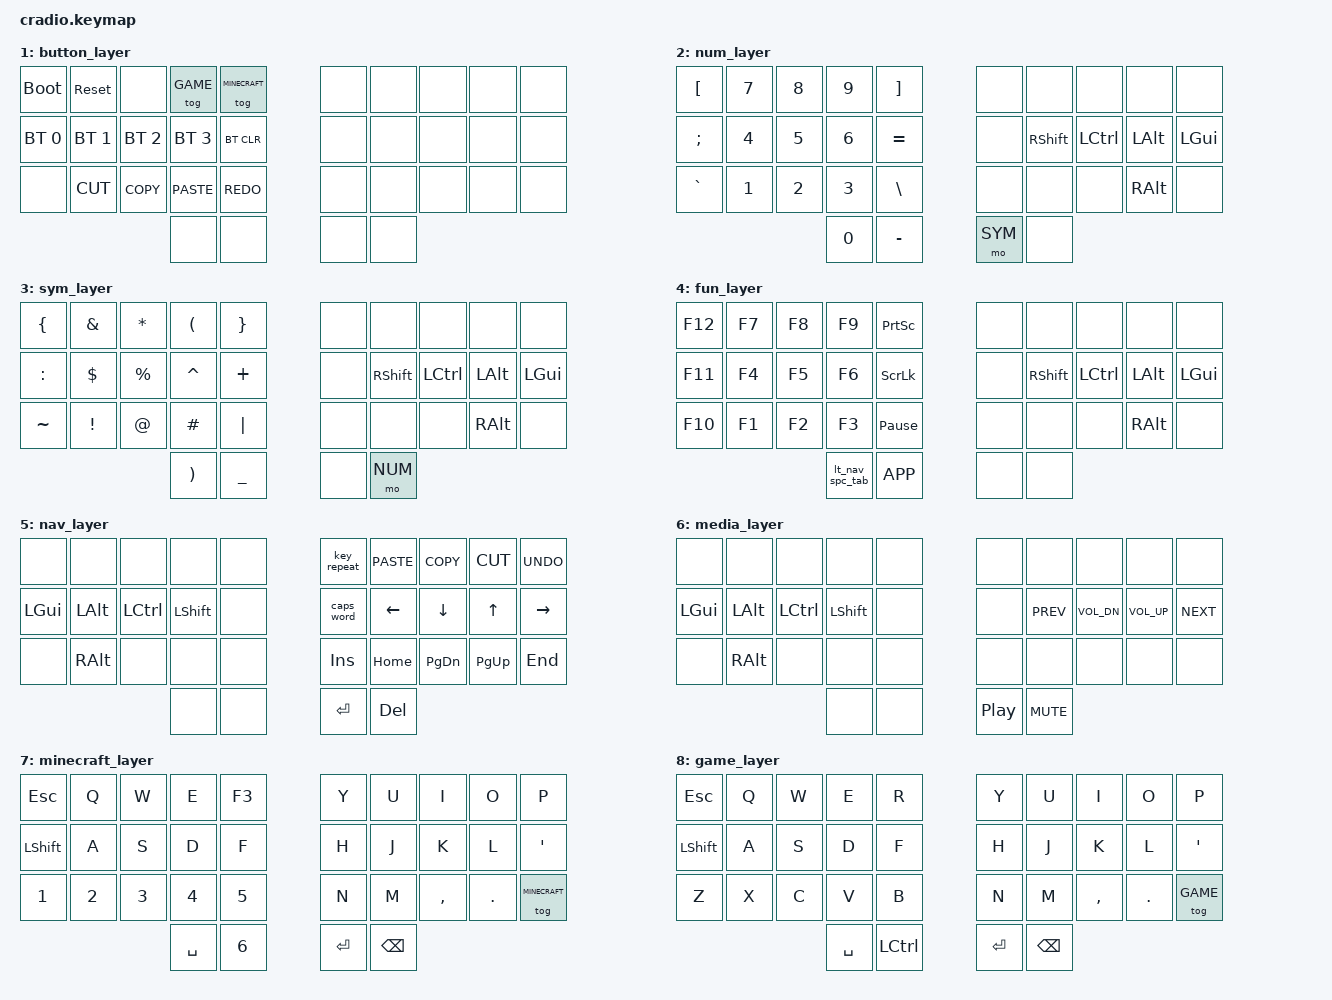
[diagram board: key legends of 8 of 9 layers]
// Copyright (c) 2022 The ZMK Contributors
// SPDX-License-Identifier: MIT

#include <behaviors.dtsi>
#include <dt-bindings/zmk/keys.h>
#include <dt-bindings/zmk/bt.h>

#define HOST_OS 1 // sets os to linux, necessary for unicode characters
#include "zmk-helpers/helper.h"
#include "zmk-helpers/unicode-chars/danish.dtsi"

// Home row mods macro
#define HRML(k1,k2,k3,k4) &ht LGUI  k1  &ht LALT  k2  &ht LCTRL k3  &ht LSHFT k4
#define HRMR(k1,k2,k3,k4) &ht RSHFT k1  &ht LCTRL k2  &ht LALT  k3  &ht LGUI  k4
#define HRML_R3(k2,k3,k4) &ht LALT  k2  &ht LCTRL k3  &ht LSHFT k4

#define BASE      0
#define BUTTON    1
#define NUM       2
#define SYM       3
#define FUN       4
#define NAV       5
#define MEDIA     6
#define MINECRAFT 7
#define GAME      8
// #define MOUSE  9

/ {
    behaviors {
        ht: hold_tap {
            compatible = "zmk,behavior-hold-tap";
            #binding-cells = <2>;
            flavor = "tap-preferred";
            tapping-term-ms = <220>;
            quick-tap-ms = <150>;
            require-prior-idle-ms = <100>;
            bindings = <&kp>, <&kp>;
        };
        lt_nav_spc_tab_ctrl: lt_nav_space_tab_ctrl {
            compatible = "zmk,behavior-mod-morph";
            #binding-cells = <0>;
            bindings = <&lt NAV TAB>, <&lt NAV LS(LC(SPACE))>;
            mods = <(MOD_LCTL|MOD_RCTL)>;
        };     
        lt_nav_spc_tab: lt_nav_space_tab {
            compatible = "zmk,behavior-mod-morph";
            #binding-cells = <0>;
            bindings = <&lt NAV SPACE>, <&lt_nav_spc_tab_ctrl>;
            mods = <(MOD_RSFT)>;
        };     
        lt_num_bspc_del: lt_num_backspace_delete {
            compatible = "zmk,behavior-mod-morph";
            #binding-cells = <0>;
            bindings = <&lt NUM BACKSPACE>, <&lt NUM DELETE>;
            mods = <(MOD_LSFT|MOD_RSFT)>;
        };
        // e_ae: ht_gui_e_ae {
        //     compatible = "zmk,behavior-mod-morph";
        //     #binding-cells = <0>;
        //     bindings = <&kp E>, <&kp &da_ae>;
        //     mods = <(MOD_LALT|MOD_RALT)>;
        // };
        // o_oe: ht_gui_o_oe {
        //     compatible = "zmk,behavior-mod-morph";
        //     #binding-cells = <0>;
        //     bindings = <&kp O>, <&kp &da_oe>;
        //     mods = <(MOD_LALT|MOD_RALT)>;
        // };
        // gui_a_aa: ht_gui_a_aa {
        //     compatible = "zmk,behavior-mod-morph";
        //     #binding-cells = <0>;
        //     bindings = <&ht LGUI A>, <&ht LGUI &da_aa>;
        //     mods = <(MOD_LALT|MOD_RALT)>;
        // };
    };

    conditional_layers {
        compatible = "zmk,conditional-layers";
        tri_layer {
            if-layers = <NUM SYM>;
            then-layer = <FUN>;
        };
    };

    keymap {
        compatible = "zmk,keymap";
        default_layer {
            bindings = <
        //╭──────────┬──────────┬──────────┬──────────┬──────────╮   ╭──────────┬──────────┬──────────┬──────────┬──────────╮
        //│  Q       │  W       │  E       │  R       │  T       │   │  Y       │  U       │  I       │  O       │  P       │
             &kp Q      &kp W      &kp E      &kp R      &kp T          &kp Y      &kp U      &kp I      &kp O      &kp P
        //├──────────┼──────────┼──────────┼──────────┼──────────┤   ├──────────┼──────────┼──────────┼──────────┼──────────┤
        //│  A       │  S       │  D       │  F       │  G       │   │  H       │  J       │  K       │  L       │ ' "      │
            HRML(A,     S,         D,         F)         &kp G          &kp H      HRMR(J,        K,         L,        SQT)
        //├──────────┼──────────┼──────────┼──────────┼──────────┤   ├──────────┼──────────┼──────────┼──────────┼──────────┤
        //│  Z       │  X       │  C       │  V       │  B       │   │  N       │  M       │ , <      │ . >      │ / ?      │
          &lt BUTTON Z &ht RALT X  &kp C      &kp V      &kp B          &kp N      &kp M    &kp COMMA &ht RALT DOT &kp FSLH
        //╰──────────┴──────────┴──────────┼──────────┼──────────┤   ├──────────┼──────────┼──────────┴──────────┴──────────╯
                                      &lt_nav_spc_tab &lt MEDIA ESC &lt SYM ENTER &lt_num_bspc_del
        //                                 ╰──────────┴──────────╯   ╰──────────┴──────────╯
            >;
        };

        button_layer {
          bindings = <
        //╭──────────┬──────────┬──────────┬──────────┬──────────╮   ╭──────────┬──────────┬──────────┬──────────┬──────────╮
        //│          │          │          │          │          │   │          │          │          │          │          │
           &bootloader &sys_reset  &none    &tog GAME &tog MINECRAFT    &none      &none      &none      &none      &none
        //├──────────┼──────────┼──────────┼──────────┼──────────┤   ├──────────┼──────────┼──────────┼──────────┼──────────┤
        //│          │          │          │          │          │   │          │          │          │          │          │
       &bt BT_SEL 0 &bt BT_SEL 1 &bt BT_SEL 2 &bt BT_SEL 3 &bt BT_CLR   &none      &none      &none      &none      &none
        //├──────────┼──────────┼──────────┼──────────┼──────────┤   ├──────────┼──────────┼──────────┼──────────┼──────────┤
        //│          │          │          │          │          │   │          │          │          │          │          │
             &none    &kp K_CUT  &kp K_COPY &kp K_PASTE &kp K_REDO      &none      &none      &none      &none      &none
        //╰──────────┴──────────┴──────────┼──────────┼──────────┤   ├──────────┼──────────┼──────────┴──────────┴──────────╯
                                              &none      &none          &none      &none
        //                                 ╰──────────┴──────────╯   ╰──────────┴──────────╯
          >;
        };

        num_layer {
            bindings = <
        //╭──────────┬──────────┬──────────┬──────────┬──────────╮   ╭──────────┬──────────┬──────────┬──────────┬──────────╮
        //│          │          │          │          │          │   │          │          │          │          │          │
            &kp LBKT    &kp N7     &kp N8     &kp N9    &kp RBKT        &none      &none      &none      &none      &none     
        //├──────────┼──────────┼──────────┼──────────┼──────────┤   ├──────────┼──────────┼──────────┼──────────┼──────────┤
        //│          │          │          │          │          │   │          │          │          │          │          │
            &kp SEMI    &kp N4     &kp N5     &kp N6    &kp EQUAL       &none    &kp RSHIFT  &kp LCTRL  &kp LALT   &kp LGUI
        //├──────────┼──────────┼──────────┼──────────┼──────────┤   ├──────────┼──────────┼──────────┼──────────┼──────────┤
        //│          │          │          │          │          │   │          │          │          │          │          │
            &kp GRAVE   &kp N1     &kp N2     &kp N3    &kp BSLH        &none      &none      &none     &kp RALT    &none     
        //╰──────────┴──────────┴──────────┼──────────┼──────────┤   ├──────────┼──────────┼──────────┴──────────┴──────────╯
                                              &kp N0    &kp MINUS      &mo SYM     &none        
        //                                 ╰──────────┴──────────╯   ╰──────────┴──────────╯
             >;
        };

        sym_layer {
          bindings = <
        //╭──────────┬──────────┬──────────┬──────────┬──────────╮   ╭──────────┬──────────┬──────────┬──────────┬──────────╮
        //│          │          │          │          │          │   │          │          │          │          │          │
            &kp LBRC   &kp AMPS   &kp STAR   &kp LPAR   &kp RBRC        &none      &none      &none      &none      &none    
        //├──────────┼──────────┼──────────┼──────────┼──────────┤   ├──────────┼──────────┼──────────┼──────────┼──────────┤
        //│          │          │          │          │          │   │          │          │          │          │          │
            &kp COLON  &kp DLLR   &kp PRCNT  &kp CARET  &kp PLUS        &none    &kp RSHIFT  &kp LCTRL  &kp LALT   &kp LGUI
        //├──────────┼──────────┼──────────┼──────────┼──────────┤   ├──────────┼──────────┼──────────┼──────────┼──────────┤
        //│          │          │          │          │          │   │          │          │          │          │          │
            &kp TILDE  &kp EXCL    &kp AT    &kp HASH   &kp PIPE        &none      &none      &none     &kp RALT    &none    
        //╰──────────┴──────────┴──────────┼──────────┼──────────┤   ├──────────┼──────────┼──────────┴──────────┴──────────╯
                                             &kp RPAR   &kp UNDER       &none     &mo NUM        
        //                                 ╰──────────┴──────────╯   ╰──────────┴──────────╯                                 
          >;
        };

        fun_layer {
          bindings = <
        //╭──────────┬──────────┬──────────┬──────────┬──────────╮   ╭──────────┬──────────┬──────────┬──────────┬──────────╮
        //│          │          │          │          │          │   │          │          │          │          │          │
            &kp F12     &kp F7     &kp F8     &kp F9   &kp PSCRN        &none      &none      &none      &none      &none    
        //├──────────┼──────────┼──────────┼──────────┼──────────┤   ├──────────┼──────────┼──────────┼──────────┼──────────┤
        //│          │          │          │          │          │   │          │          │          │          │          │
            &kp F11     &kp F4     &kp F5     &kp F6   &kp SLCK         &none    &kp RSHIFT  &kp LCTRL  &kp LALT   &kp LGUI
        //├──────────┼──────────┼──────────┼──────────┼──────────┤   ├──────────┼──────────┼──────────┼──────────┼──────────┤
        //│          │          │          │          │          │   │          │          │          │          │          │
            &kp F10     &kp F1     &kp F2     &kp F3 &kp PAUSE_BREAK    &none      &none      &none     &kp RALT    &none    
        //╰──────────┴──────────┴──────────┼──────────┼──────────┤   ├──────────┼──────────┼──────────┴──────────┴──────────╯
                                       &lt_nav_spc_tab &kp K_APP        &none      &none        
        //                                 ╰──────────┴──────────╯   ╰──────────┴──────────╯                                 
          >;
        };

        nav_layer {
          bindings = <
        //╭──────────┬──────────┬──────────┬──────────┬──────────╮   ╭──────────┬──────────┬──────────┬──────────┬──────────╮
        //│          │          │          │          │          │   │          │          │          │          │          │
             &none      &none      &none      &none      &none       &key_repeat &kp K_PASTE &kp K_COPY &kp K_CUT  &kp K_UNDO
        //├──────────┼──────────┼──────────┼──────────┼──────────┤   ├──────────┼──────────┼──────────┼──────────┼──────────┤
        //│          │          │          │          │          │   │          │          │          │          │          │
            &kp LGUI   &kp LALT   &kp LCTRL &kp LSHIFT   &none        &caps_word  &kp LEFT   &kp DOWN    &kp UP   &kp RIGHT 
        //├──────────┼──────────┼──────────┼──────────┼──────────┤   ├──────────┼──────────┼──────────┼──────────┼──────────┤
        //│          │          │          │          │          │   │          │          │          │          │          │
             &none     &kp RALT    &none      &none      &none          &kp INS   &kp HOME   &kp PG_DN  &kp PG_UP  &kp END
        //╰──────────┴──────────┴──────────┼──────────┼──────────┤   ├──────────┼──────────┼──────────┴──────────┴──────────╯
                                              &none      &none         &kp ENTER  &kp DEL
        //                                 ╰──────────┴──────────╯   ╰──────────┴──────────╯
          >;
        };

        media_layer {
          bindings = <
        //╭──────────┬──────────┬──────────┬──────────┬──────────╮   ╭──────────┬──────────┬──────────┬──────────┬──────────╮
        //│          │          │          │          │          │   │          │          │          │          │          │
             &none      &none      &none      &none      &none          &none      &none      &none      &none      &none    
        //├──────────┼──────────┼──────────┼──────────┼──────────┤   ├──────────┼──────────┼──────────┼──────────┼──────────┤
        //│          │          │          │          │          │   │          │          │          │          │          │
            &kp LGUI   &kp LALT   &kp LCTRL &kp LSHIFT   &none          &none  &kp C_PREV &kp C_VOL_DN &kp C_VOL_UP &kp C_NEXT
        //├──────────┼──────────┼──────────┼──────────┼──────────┤   ├──────────┼──────────┼──────────┼──────────┼──────────┤
        //│          │          │          │          │          │   │          │          │          │          │          │
             &none     &kp RALT    &none      &none      &none          &none      &none      &none      &none      &none              
        //╰──────────┴──────────┴──────────┼──────────┼──────────┤   ├──────────┼──────────┼──────────┴──────────┴──────────╯
                                              &none      &none     &kp C_PLAY_PAUSE &kp C_MUTE
        //                                 ╰──────────┴──────────╯   ╰──────────┴──────────╯
          >;
        };

        minecraft_layer {
            bindings = <
        //╭──────────┬──────────┬──────────┬──────────┬──────────╮   ╭──────────┬──────────┬──────────┬──────────┬──────────╮
        //│  Q       │  W       │  E       │  R       │  T       │   │  Y       │  U       │  I       │  O       │  P       │
            &kp ESC    &kp Q      &kp W      &kp E      &kp F3          &kp Y      &kp U      &kp I      &kp O      &kp P
        //├──────────┼──────────┼──────────┼──────────┼──────────┤   ├──────────┼──────────┼──────────┼──────────┼──────────┤
        //│  A       │  S       │  D       │  F       │  G       │   │  H       │  J       │  K       │  L       │ ' "      │
            &kp LSHFT  &kp A      &kp S      &kp D      &kp F          &kp H      &kp J      &kp K      &kp L      &kp SQT
        //├──────────┼──────────┼──────────┼──────────┼──────────┤   ├──────────┼──────────┼──────────┼──────────┼──────────┤
        //│  Z       │  X       │  C       │  V       │  B       │   │  N       │  M       │ , <      │ . >      │ / ?      │
            &kp N1     &kp N2     &kp N3     &kp N4     &kp N5         &kp N      &kp M     &kp COMMA   &kp DOT  &tog MINECRAFT
        //╰──────────┴──────────┴──────────┼──────────┼──────────┤   ├──────────┼──────────┼──────────┴──────────┴──────────╯
                                             &kp SPACE  &kp N6         &kp ENTER  &kp BACKSPACE
        //                                 ╰──────────┴──────────╯   ╰──────────┴──────────╯
            >;
        };

        game_layer {
            bindings = <
        //╭──────────┬──────────┬──────────┬──────────┬──────────╮   ╭──────────┬──────────┬──────────┬──────────┬──────────╮
        //│  Q       │  W       │  E       │  R       │  T       │   │  Y       │  U       │  I       │  O       │  P       │
            &kp ESC    &kp Q      &kp W      &kp E      &kp R          &kp Y      &kp U      &kp I      &kp O      &kp P
        //├──────────┼──────────┼──────────┼──────────┼──────────┤   ├──────────┼──────────┼──────────┼──────────┼──────────┤
        //│  A       │  S       │  D       │  F       │  G       │   │  H       │  J       │  K       │  L       │ ' "      │
            &kp LSHFT  &kp A      &kp S      &kp D      &kp F          &kp H      &kp J      &kp K      &kp L      &kp SQT
        //├──────────┼──────────┼──────────┼──────────┼──────────┤   ├──────────┼──────────┼──────────┼──────────┼──────────┤
        //│  Z       │  X       │  C       │  V       │  B       │   │  N       │  M       │ , <      │ . >      │ / ?      │
            &kp Z      &kp X      &kp C      &kp V      &kp B          &kp N      &kp M     &kp COMMA   &kp DOT    &tog GAME
        //╰──────────┴──────────┴──────────┼──────────┼──────────┤   ├──────────┼──────────┼──────────┴──────────┴──────────╯
                                             &kp SPACE  &kp LCTRL      &kp ENTER  &kp BACKSPACE
        //                                 ╰──────────┴──────────╯   ╰──────────┴──────────╯
            >;
        };
        // mouse_layer {
        //   bindings = <
        // //╭──────────┬──────────┬──────────┬──────────┬──────────╮   ╭──────────┬──────────┬──────────┬──────────┬──────────╮
        // //│          │          │          │          │          │   │          │          │          │          │          │
        //      &none      &none      &none      &none      &none       &key_repeat &kp K_PASTE &kp K_COPY &kp K_CUT  &kp K_UNDO
        // //├──────────┼──────────┼──────────┼──────────┼──────────┤   ├──────────┼──────────┼──────────┼──────────┼──────────┤
        // //│          │          │          │          │          │   │          │          │          │          │          │
        //      &none      &none      &none      &none      &none          &none
        // //├──────────┼──────────┼──────────┼──────────┼──────────┤   ├──────────┼──────────┼──────────┼──────────┼──────────┤
        // //│          │          │          │          │          │   │          │          │          │          │          │
        //      &none      &none      &none      &none      &none          &none 
        // //╰──────────┴──────────┴──────────┼──────────┼──────────┤   ├──────────┼──────────┼──────────┴──────────┴──────────╯
        //                                       &none      &none        &mkp LCLK  &mkp RCLK
        // //                                 ╰──────────┴──────────╯   ╰──────────┴──────────╯
        //   >;
        // };

        // fun_layer {
        //   bindings = <
        // //╭──────────┬──────────┬──────────┬──────────┬──────────╮   ╭──────────┬──────────┬──────────┬──────────┬──────────╮
        // //│          │          │          │          │          │   │          │          │          │          │          │
        // 
        // //├──────────┼──────────┼──────────┼──────────┼──────────┤   ├──────────┼──────────┼──────────┼──────────┼──────────┤
        // //│          │          │          │          │          │   │          │          │          │          │          │

        // //├──────────┼──────────┼──────────┼──────────┼──────────┤   ├──────────┼──────────┼──────────┼──────────┼──────────┤
        // //│          │          │          │          │          │   │          │          │          │          │          │

        // //╰──────────┴──────────┴──────────┼──────────┼──────────┤   ├──────────┼──────────┼──────────┴──────────┴──────────╯

        // //                                 ╰──────────┴──────────╯   ╰──────────┴──────────╯
        //   >;
        // };

        //╭──────────┬──────────┬──────────┬──────────┬──────────╮   ╭──────────┬──────────┬──────────┬──────────┬──────────╮
        //│          │          │          │          │          │   │          │          │          │          │          │
        
        //├──────────┼──────────┼──────────┼──────────┼──────────┤   ├──────────┼──────────┼──────────┼──────────┼──────────┤
        //│          │          │          │          │          │   │          │          │          │          │          │

        //├──────────┼──────────┼──────────┼──────────┼──────────┤   ├──────────┼──────────┼──────────┼──────────┼──────────┤
        //│          │          │          │          │          │   │          │          │          │          │          │

        //╰──────────┴──────────┴──────────┼──────────┼──────────┤   ├──────────┼──────────┼──────────┴──────────┴──────────╯

        //                                 ╰──────────┴──────────╯   ╰──────────┴──────────╯

        // left_layer {
        //     bindings = <
        // //╭──────────┬──────────┬──────────┬──────────┬──────────╮   ╭──────────┬──────────┬──────────┬──────────┬──────────╮
        // //│          │  [       │  {       │  }       │          │   │  ^       │  (       │  )       │  ]       │  ~       │
        //     &trans     &kp LBKT   &kp LBRC   &kp RBRC   &trans         &kp CARET  &kp LPAR   &kp RPAR   &kp RBKT   &kp TILDE
        // //├──────────┼──────────┼──────────┼──────────┼──────────┤   ├──────────┼──────────┼──────────┼──────────┼──────────┤
        // //│  !       │  @       │  #       │  $       │  %       │   │  *       │  -       │  =       │  \       │  `       │
        //     &kp EXCL   &kp AT     &kp HASH   &kp DLLR   &kp PRCNT      &kp ASTRK  &kp MINUS  &kp EQUAL  &kp BSLH   &kp GRAVE
        // //├──────────┼──────────┼──────────┼──────────┼──────────┤   ├──────────┼──────────┼──────────┼──────────┼──────────┤
        // //│          │          │          │          │          │   │  &       │  _       │  +       │  │       │          │
        //     &trans     &trans     &trans     &trans     &trans         &kp AMPS   &kp UNDER  &kp PLUS   &kp PIPE   &trans
        // //╰──────────┴──────────┴──────────┼──────────┼──────────┤   ├──────────┼──────────┼──────────┴──────────┴──────────╯
        //                                      &trans     &trans         &trans     &trans
        // //                                 ╰──────────┴──────────╯   ╰──────────┴──────────╯
        //     >;
        // };

        // tri_layer {
        //     bindings = <
        // //╭──────────┬──────────┬──────────┬──────────┬──────────╮   ╭──────────┬──────────┬──────────┬──────────┬──────────╮
        // //│ RESET    │          │          │          │PROFILE 0 │   │          │          │          │          │  RESET   │
        //    &sys_reset  &trans     &trans     &trans    &bt BT_SEL 0    &trans     &trans     &trans     &trans    &sys_reset
        // //├──────────┼──────────┼──────────┼──────────┼──────────┤   ├──────────┼──────────┼──────────┼──────────┼──────────┤
        // //│BOOTLOADER│          │          │          │PROFILE 1 │   │          │          │          │          │BOOTLOADER│
        //   &bootloader  &trans     &trans     &trans    &bt BT_SEL 1    &trans     &trans     &trans     &trans    &bootloader
        // //├──────────┼──────────┼──────────┼──────────┼──────────┤   ├──────────┼──────────┼──────────┼──────────┼──────────┤
        // //│          │          │          │ CLEAR BT │PROFILE 2 │   │          │          │          │          │          │
        //     &trans     &trans     &trans    &bt BT_CLR &bt BT_SEL 2    &trans     &trans     &trans     &trans     &trans
        // //╰──────────┴──────────┴──────────┼──────────┼──────────┤   ├──────────┼──────────┼──────────┴──────────┴──────────╯
        //                                      &trans     &trans         &trans     &trans
        // //                                 ╰──────────┴──────────╯   ╰──────────┴──────────╯
        //     >;
        // };
    };
};





//   /*
//   * Copyright (c) 2020 The ZMK Contributors
//   *
//   * SPDX-License-Identifier: MIT
//   */
// 
//   #include <behaviors.dtsi>
//   #include <dt-bindings/zmk/keys.h>
//   #include <dt-bindings/zmk/bt.h>
//   #include <dt-bindings/zmk/ext_power.h>
// 
//   / {
//     behaviors {
//         ht: hold_tap {
//             compatible = "zmk,behavior-hold-tap";
//             #binding-cells = <2>;
//             flavor = "tap-preferred";
//             tapping-term-ms = <220>;
//             quick-tap-ms = <150>;
//             require-prior-idle-ms = <100>;
//             bindings = <&kp>, <&kp>;
//         };
//     };
// 
//     keymap {
//       compatible = "zmk,keymap";
//   layer0 {
//           bindings = <
//             &kp ESCAPE &kp Q &kp W &kp E &kp R &kp T &kp Y &kp U &kp I &kp O &kp P [[UP(AA_LOWER_INDEX, AA_UPPER_INDEX)]] 
//             &mt LEFT_SHIFT CAPSLOCK &mt LEFT_GUI A &mt LEFT_ALT S &mt LEFT_CONTROL D &mt LEFT_SHIFT F &kp G &kp H &mt LEFT_SHIFT J &mt LEFT_CONTROL K &mt LEFT_ALT L &mt LEFT_GUI SINGLE_QUOTE [[UP(AE_LOWER_INDEX, AE_UPPER_INDEX)]] 
//             &none &lt U_BUTTON Z [[ALGR_T(KC_X)]] &kp C &kp V &kp B &kp N &kp M &kp COMMA [[ALGR_T(KC_DOT)]] &lt U_BUTTON SLASH [[KC_UNDS]] 
//             &lt U_MEDIA ESCAPE &lt U_NAV SPACE &lt U_MOUSE TAB &lt U_SYM ENTER &lt U_NUM BACKSPACE &lt U_FUN DELETE
//           >;
//         };layer1 {
//           bindings = <
//           &kp ESCAPE &kp Q &kp T &kp W &kp E &kp R &kp Y &kp U &kp I &kp O &kp P [[TD(U_TD_U_BASE)]] &kp TAB &kp H &kp A &kp S &kp D &kp F &kp H &mt LEFT_SHIFT J &mt LEFT_CONTROL K &mt LEFT_ALT L &mt LEFT_GUI SINGLE_QUOTE [[TD(U_TD_U_BASE)]] &kp LEFT_ALT &kp Z &kp X &kp C &kp V &kp B &kp N &kp M &kp COMMA [[ALGR_T(KC_DOT)]] &lt U_BUTTON SLASH [[TD(U_TD_U_BASE)]] &kp LEFT_SHIFT &kp SPACE &kp LEFT_CONTROL &kp ENTER &kp BACKSPACE &kp DELETE
//           >;
//         };layer2 {
//           bindings = <
//           &none &kp Q &kp W &kp E &kp R &kp T &kp Z &kp U &kp I &kp O &kp P &none &none &kp A &kp S &kp D &kp F &kp G &kp H &kp J &kp K &kp L &kp SINGLE_QUOTE &none &none &kp Y &kp X &kp C &kp V &kp B &kp N &kp M &kp COMMA &kp DOT &kp SLASH &none &kp ESCAPE &kp SPACE &kp TAB &kp ENTER &kp BACKSPACE &kp DELETE
//           >;
//         };layer3 {
//           bindings = <
//           [[TD(QK_MAKE)]] &kp K_UNDO &kp K_CUT &kp K_COPY &kp K_PASTE &kp K_AGAIN &kp K_AGAIN &kp K_PASTE &kp K_COPY &kp K_CUT &kp K_UNDO [[TD(QK_MAKE)]] &none &kp LEFT_GUI &kp LEFT_ALT &kp LEFT_CONTROL &kp LEFT_SHIFT &none &none &kp LEFT_SHIFT &kp LEFT_CONTROL &kp LEFT_ALT &kp LEFT_GUI &none &none &kp K_UNDO &kp K_CUT &kp K_COPY &kp K_PASTE &kp K_AGAIN &kp K_AGAIN &kp K_PASTE &kp K_COPY &kp K_CUT &kp K_UNDO &none [[KC_BTN3]] [[KC_BTN1]] [[KC_BTN2]] [[KC_BTN2]] [[KC_BTN1]] [[KC_BTN3]]
//           >;
//         };layer4 {
//           bindings = <
//           &kp F21 [[TD(U_TD_BOOT)]] [[TD(U_TD_U_TAP)]] [[TD(U_TD_U_GAME)]] [[TD(U_TD_U_BASE)]] &none &kp K_AGAIN &kp K_PASTE &kp K_COPY &kp K_CUT &kp K_UNDO &none &kp F20 &kp LEFT_GUI &kp LEFT_ALT &kp LEFT_CONTROL &kp LEFT_SHIFT &none [[CW_TOGG]] &kp LEFT &kp DOWN &kp UP &kp RIGHT [[UP(OE_LOWER_INDEX, OE_UPPER_INDEX)]] &kp F19 &none &kp RIGHT_ALT [[TD(U_TD_U_NUM)]] [[TD(U_TD_U_NAV)]] &none &kp INSERT &kp HOME &kp PAGE_DOWN &kp PAGE_UP &kp END &none &none &none &none &kp ENTER &kp BACKSPACE &kp DELETE
//           >;
//         };layer5 {
//           bindings = <
//           &kp F21 [[TD(U_TD_BOOT)]] [[TD(U_TD_U_TAP)]] [[TD(U_TD_U_GAME)]] [[TD(U_TD_U_BASE)]] &none &kp K_AGAIN &kp K_PASTE &kp K_COPY &kp K_CUT &kp K_UNDO [[KC_RCBR]] &kp F20 &kp LEFT_GUI &kp LEFT_ALT &kp LEFT_CONTROL &kp LEFT_SHIFT &none &none [[KC_MS_L]] [[KC_MS_D]] [[KC_MS_U]] [[KC_MS_R]] [[KC_RPRN]] &kp F19 &none &kp RIGHT_ALT [[TD(U_TD_U_SYM)]] [[TD(U_TD_U_MOUSE)]] &none &none [[KC_WH_L]] [[KC_WH_D]] [[KC_WH_U]] [[KC_WH_R]] &kp RIGHT_BRACKET &none &none &none [[KC_BTN2]] [[KC_BTN1]] [[KC_BTN3]]
//           >;
//         };layer6 {
//           bindings = <
//           &kp F21 [[TD(U_TD_BOOT)]] [[TD(U_TD_U_TAP)]] [[TD(U_TD_U_GAME)]] [[TD(U_TD_U_BASE)]] &none [[RGB_TOG]] [[RGB_MOD]] [[RGB_HUI]] [[RGB_SAI]] [[RGB_VAI]] [[KC_LCBR]] &kp F20 &kp LEFT_GUI &kp LEFT_ALT &kp LEFT_CONTROL &kp LEFT_SHIFT &none &none &kp C_PREVIOUS &kp C_VOLUME_DOWN &kp C_VOLUME_UP &kp C_NEXT [[KC_LPRN]] &kp F19 &none &kp RIGHT_ALT [[TD(U_TD_U_FUN)]] [[TD(U_TD_U_MEDIA)]] &none [[OU_AUTO]] &none &none &none &none &kp LEFT_BRACKET &none &none &none &kp C_STOP &kp C_PLAY_PAUSE &kp C_MUTE
//           >;
//         };layer7 {
//           bindings = <
//           &kp KP_PLUS &kp LEFT_BRACKET &kp N7 &kp N8 &kp N9 &kp RIGHT_BRACKET &none [[TD(U_TD_U_BASE)]] [[TD(U_TD_U_GAME)]] [[TD(U_TD_U_TAP)]] [[TD(U_TD_BOOT)]] &kp F18 &kp KP_MINUS &kp SEMICOLON &kp N4 &kp N5 &kp N6 &kp EQUAL &none &kp LEFT_SHIFT &kp LEFT_CONTROL &kp LEFT_ALT &kp LEFT_GUI &kp F17 [[KC_PIPE]] &kp GRAVE &kp N1 &kp N2 &kp N3 &kp BACKSLASH &none [[TD(U_TD_U_NUM)]] [[TD(U_TD_U_NAV)]] &kp RIGHT_ALT &none &kp F16 &kp DOT &kp N0 &kp MINUS &none &none &none
//           >;
//         };layer8 {
//           bindings = <
//           [[KC_ASTR]] [[KC_LCBR]] [[KC_AMPR]] [[KC_ASTR]] [[KC_LPRN]] [[KC_RCBR]] &none [[TD(U_TD_U_BASE)]] [[TD(U_TD_U_GAME)]] [[TD(U_TD_U_TAP)]] [[TD(U_TD_BOOT)]] &kp F18 &kp SLASH [[KC_COLN]] [[KC_DLR]] [[KC_PERC]] [[KC_CIRC]] [[KC_PLUS]] &none &kp LEFT_SHIFT &kp LEFT_CONTROL &kp LEFT_ALT &kp LEFT_GUI &kp F17 [[KC_AMPR]] [[KC_TILD]] [[KC_EXLM]] [[KC_AT]] [[KC_HASH]] [[KC_PIPE]] &none [[TD(U_TD_U_SYM)]] [[TD(U_TD_U_MOUSE)]] &kp RIGHT_ALT &none &kp F16 [[KC_LPRN]] [[KC_RPRN]] [[KC_UNDS]] &none &none &none
//           >;
//         };layer9 {
//           bindings = <
//           &kp F15 &kp F12 &kp F7 &kp F8 &kp F9 &kp PRINTSCREEN &none [[TD(U_TD_U_BASE)]] [[TD(U_TD_U_GAME)]] [[TD(U_TD_U_TAP)]] [[TD(U_TD_BOOT)]] &kp F18 &kp F14 &kp F11 &kp F4 &kp F5 &kp F6 &kp SCROLLLOCK &none &kp LEFT_SHIFT &kp LEFT_CONTROL &kp LEFT_ALT &kp LEFT_GUI &kp F17 &kp F13 &kp F10 &kp F1 &kp F2 &kp F3 &kp PAUSE_BREAK &none [[TD(U_TD_U_FUN)]] [[TD(U_TD_U_MEDIA)]] &kp RIGHT_ALT &none &kp F16 &kp K_APPLICATION &kp SPACE &kp TAB &none &none &none
//           >;
//         };
//     };
//   };
